VERSION ""

NS_ :

BS_:

BU_: EON XXX INTERCEPTOR

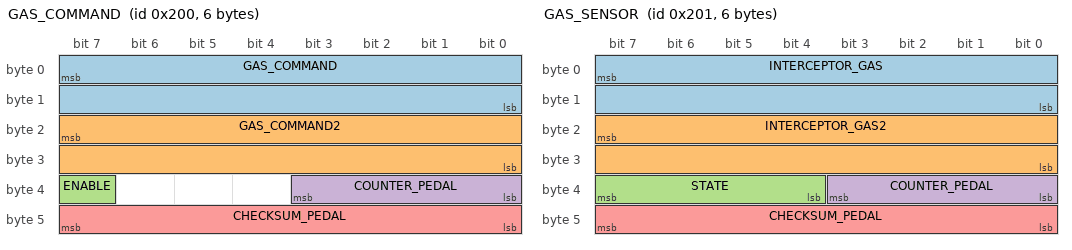
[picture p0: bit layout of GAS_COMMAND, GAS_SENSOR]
BO_ 512 GAS_COMMAND: 6 EON
 SG_ GAS_COMMAND : 7|16@0+ (0.253984064,-83.3) [0|1] "" INTERCEPTOR
 SG_ GAS_COMMAND2 : 23|16@0+ (0.126992032,-83.3) [0|1] "" INTERCEPTOR
 SG_ ENABLE : 39|1@0+ (1,0) [0|1] "" INTERCEPTOR
 SG_ COUNTER_PEDAL : 35|4@0+ (1,0) [0|15] "" INTERCEPTOR
 SG_ CHECKSUM_PEDAL : 47|8@0+ (1,0) [0|255] "" INTERCEPTOR

BO_ 513 GAS_SENSOR: 6 INTERCEPTOR
 SG_ INTERCEPTOR_GAS : 7|16@0+ (0.253984064,-83.3) [0|1] "" EON
 SG_ INTERCEPTOR_GAS2 : 23|16@0+ (0.126992032,-83.3) [0|1] "" EON
 SG_ STATE : 39|4@0+ (1,0) [0|15] "" EON
 SG_ COUNTER_PEDAL : 35|4@0+ (1,0) [0|15] "" EON
 SG_ CHECKSUM_PEDAL : 47|8@0+ (1,0) [0|255] "" EON

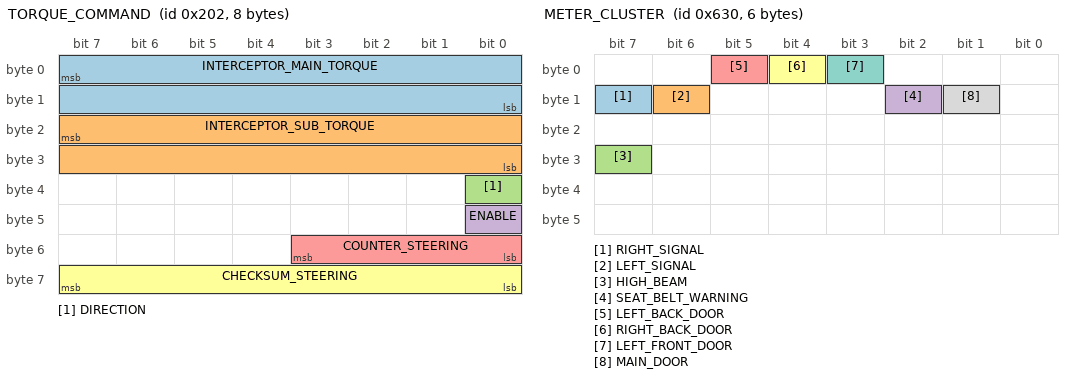
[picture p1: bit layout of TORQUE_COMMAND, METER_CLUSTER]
BO_ 514 TORQUE_COMMAND: 8 INTERCEPTOR
 SG_ INTERCEPTOR_MAIN_TORQUE : 7|16@0+ (1,0) [0|1] "" EON
 SG_ INTERCEPTOR_SUB_TORQUE : 23|16@0+ (1,0) [0|1] "" EON
 SG_ DIRECTION : 32|1@0+ (1,0) [0|1] "" EON
 SG_ ENABLE : 40|1@0+ (1,0) [0|1] "" EON
 SG_ COUNTER_STEERING : 51|4@0+ (1,0) [0|15] "" EON
 SG_ CHECKSUM_STEERING : 63|8@0+ (1,0) [0|255] "" EON

BO_ 33 BRAKE_PEDAL: 8 XXX
 SG_ BRAKE_PRESSURE : 55|8@0+ (1,0) [0|255] "" XXX
 SG_ BRAKE_ENGAGED : 5|1@0+ (1,0) [0|1] "" XXX

BO_ 107 STEERING_TORQUE: 4 XXX
 SG_ SUB_TORQUE : 31|8@0+ (1,-111) [0|255] "" XXX
 SG_ MAIN_TORQUE : 15|8@0+ (1,0) [0|255] "" XXX

BO_ 1584 METER_CLUSTER: 6 XXX
 SG_ RIGHT_SIGNAL : 15|1@0+ (1,0) [0|1] "" XXX
 SG_ LEFT_SIGNAL : 14|1@0+ (1,0) [0|1] "" XXX
 SG_ HIGH_BEAM : 31|1@0+ (1,0) [0|1] "" XXX
 SG_ SEAT_BELT_WARNING : 10|1@0+ (1,0) [0|1] "" XXX
 SG_ LEFT_BACK_DOOR : 5|1@0+ (1,0) [0|1] "" XXX
 SG_ RIGHT_BACK_DOOR : 4|1@0+ (1,0) [0|1] "" XXX
 SG_ LEFT_FRONT_DOOR : 3|1@0+ (1,0) [0|1] "" XXX
 SG_ MAIN_DOOR : 9|1@0+ (1,0) [0|1] "" XXX

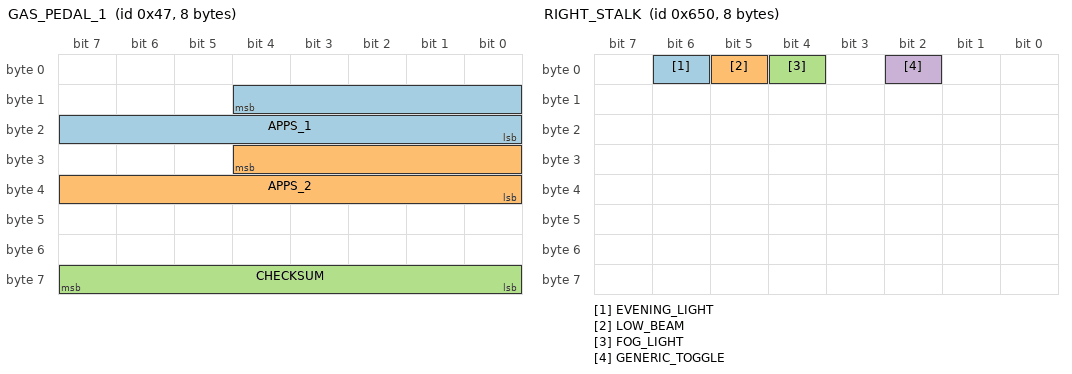
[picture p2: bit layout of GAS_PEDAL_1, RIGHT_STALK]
BO_ 71 GAS_PEDAL_1: 8 XXX
 SG_ APPS_1 : 12|13@0+ (0.00015625,0) [0|1] "" XXX
 SG_ APPS_2 : 28|13@0+ (0.00033955857,0) [0|1] "" XXX
 SG_ CHECKSUM : 63|8@0+ (1,0) [0|255] "" XXX

BO_ 76 GAS_PEDAL_2: 7 XXX

BO_ 384 HANDBRAKE: 5 XXX
 SG_ HANDBRAKE_ENGAGED : 0|1@1+ (1,0) [0|1] "" XXX

BO_ 88 TRANSMISSION: 5 XXX
 SG_ GEAR : 0|6@0+ (1,0) [0|31] "" XXX

BO_ 37 STEERING_ANGLE_SENSOR: 8 XXX
 SG_ STEER_ANGLE : 46|23@0- (0.00039246467,0) [-500|500] "deg" XXX

BO_ 1616 RIGHT_STALK: 8 XXX
 SG_ EVENING_LIGHT : 6|1@0+ (1,0) [0|1] "" XXX
 SG_ LOW_BEAM : 5|1@0+ (1,0) [0|1] "" XXX
 SG_ FOG_LIGHT : 4|1@0+ (1,0) [0|1] "" XXX
 SG_ GENERIC_TOGGLE : 2|1@0+ (1,0) [0|1] "" XXX

BO_ 679 FWD_CAM1: 8 XXX

BO_ 680 FWD_CAM2: 8 XXX

BO_ 681 FWD_CAM3: 8 XXX

BO_ 1267 FWD_CAM4: 8 XXX

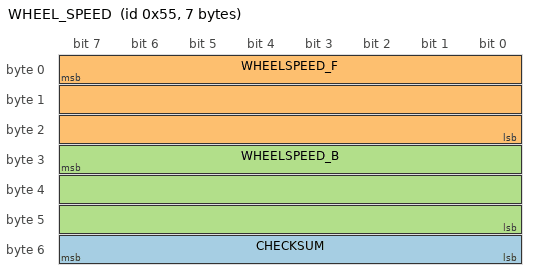
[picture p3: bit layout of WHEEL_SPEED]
BO_ 85 WHEEL_SPEED: 7 XXX
 SG_ CHECKSUM : 55|8@0+ (1,0) [0|255] "" XXX
 SG_ WHEELSPEED_F : 7|24@0+ (0.0000140,0) [0|16777215] "kph" XXX
 SG_ WHEELSPEED_B : 31|24@0+ (0.0000036,0) [0|16777215] "kph" XXX

CM_ SG_ 384 HANDBRAKE_ENGAGED "1 = handbrake engaged";
VAL_ 513 STATE 5 "FAULT_TIMEOUT" 4 "FAULT_STARTUP" 3 "FAULT_SCE" 2 "FAULT_SEND" 1 "FAULT_BAD_CHECKSUM" 0 "NO_FAULT" ;
VAL_ 514 STATE 5 "FAULT_TIMEOUT" 4 "FAULT_STARTUP" 3 "FAULT_SCE" 2 "FAULT_SEND" 1 "FAULT_BAD_CHECKSUM" 0 "NO_FAULT" ;
VAL_ 88 GEAR 32 "P" 16 "R" 8 "N" 4 "D" 2 "D" 1 "D"
